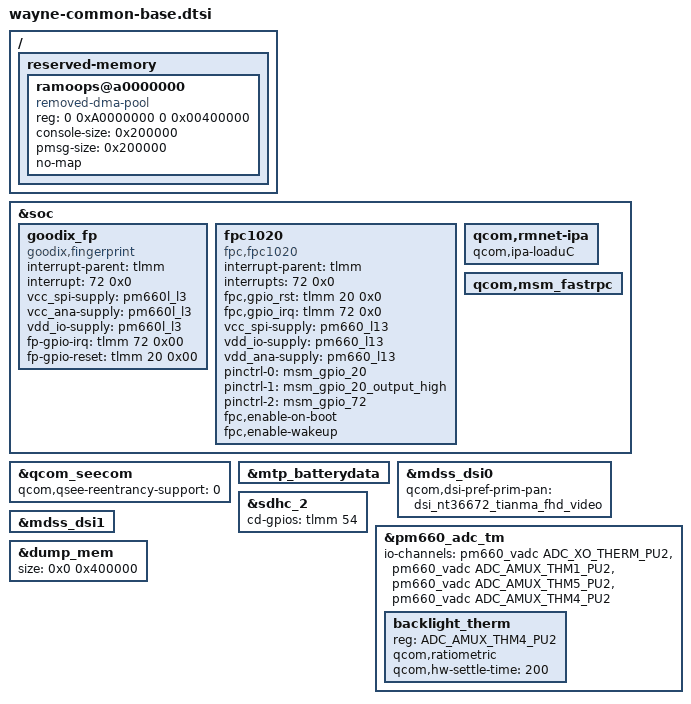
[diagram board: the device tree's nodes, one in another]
#include "pm660.dtsi"
#include "pm660l.dtsi"
#include "pm660-rpm-regulator.dtsi"
#include "sdm660-regulator.dtsi"
#include "sdm660-thermal.dtsi"
#include "sdm660-common.dtsi"
#include "sdm660-blsp.dtsi"
#include "sdm660-camera.dtsi"
#include "msm-audio.dtsi"
#include "sdm660-audio.dtsi"
#include "sdm660-mdss-panels.dtsi"

#include "sdm660-camera-sensor-mtp.dtsi"
#include "touch/sdm660-novatek-i2c_d2s.dtsi"

/ {
	reserved-memory {
		ramoops@a0000000 {
			compatible = "removed-dma-pool", "ramoops";
			reg = <0 0xA0000000 0 0x00400000>;
			console-size = <0x200000>;
			pmsg-size = <0x200000>;
			no-map;
		};
	};
};

&soc {
	/delete-node/ qcom,qbt1000;

	goodix_fp {
		compatible = "goodix,fingerprint";
		interrupt-parent = <&tlmm>;
		interrupt = <72 0x0>;
		vcc_spi-supply = <&pm660l_l3>;
		vcc_ana-supply = <&pm660l_l3>;
		vdd_io-supply = <&pm660l_l3>;
		fp-gpio-irq = <&tlmm 72 0x00>;
		fp-gpio-reset = <&tlmm 20 0x00>;
		status = "okay";
	};

	fpc1020 {
		status = "ok";
		compatible = "fpc,fpc1020";
		interrupt-parent = <&tlmm>;
		interrupts = <72 0x0>;
		fpc,gpio_rst = <&tlmm 20 0x0>;
		fpc,gpio_irq = <&tlmm 72 0x0>;
		vcc_spi-supply = <&pm660_l13>;
		vdd_io-supply = <&pm660_l13>;
		vdd_ana-supply = <&pm660_l13>;

		pinctrl-names = "fpc1020_reset_reset",
				"fpc1020_reset_active",
				"fpc1020_irq_active";

		pinctrl-0 = <&msm_gpio_20>;
		pinctrl-1 = <&msm_gpio_20_output_high>;
		pinctrl-2 = <&msm_gpio_72>;
		fpc,enable-on-boot;
		fpc,enable-wakeup;
	};

	qcom,rmnet-ipa {
		/delete-property/ qcom,ipa-platform-type-msm;
		qcom,ipa-loaduC;
	};

	qcom,msm_fastrpc {
		/delete-property/ qcom,fastrpc-adsp-sensors-pdr;
	};
};

&qcom_seecom {
	qcom,qsee-reentrancy-support = <0>;
};

&mtp_batterydata {
	/delete-node/ qcom,itech_3000mah;
	/delete-node/ qcom,ascent_3450mah;
	#include "battery/fg-gen3-batterydata-l8866cos-3000mah.dtsi"
	#include "battery/fg-gen3-batterydata-l8866default-3000mah.dtsi"
	#include "battery/fg-gen3-batterydata-l8866sun-3000mah.dtsi"
};

&mdss_dsi0 {
	qcom,dsi-pref-prim-pan = <&dsi_nt36672_tianma_fhd_video>;
};

&sdhc_2 {
	cd-gpios = <&tlmm 54 0x0>;
};

&mdss_dsi1 {
	/delete-property/ qcom,dsi-pref-prim-pan;
	/delete-property/ pinctrl-names;
	/delete-property/ pinctrl-0;
	/delete-property/ pinctrl-1;
	/delete-property/ qcom,platform-reset-gpio;
	/delete-property/ qcom,platform-te-gpio;
};

&pm660_adc_tm {
	io-channels = <&pm660_vadc ADC_XO_THERM_PU2>,
			<&pm660_vadc ADC_AMUX_THM1_PU2>,
			<&pm660_vadc ADC_AMUX_THM5_PU2>,
			<&pm660_vadc ADC_AMUX_THM4_PU2>;

	backlight_therm {
		reg = <ADC_AMUX_THM4_PU2>;
		qcom,ratiometric;
		qcom,hw-settle-time = <200>;
	};
};

&dump_mem {
	size = <0x0 0x400000>;
};
